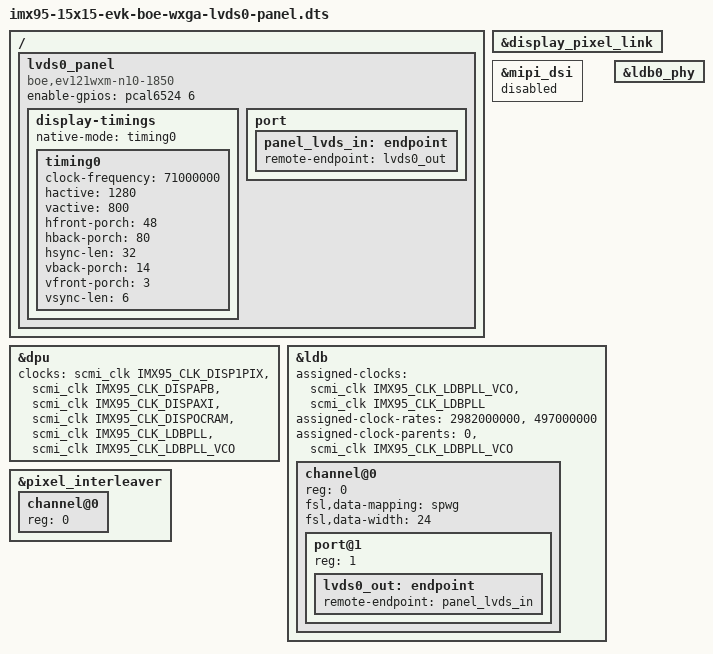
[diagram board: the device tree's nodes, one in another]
// SPDX-License-Identifier: (GPL-2.0+ OR MIT)
/*
 * Copyright 2024 NXP
 */

#include "imx95-15x15-evk.dts"
#include "imx95-15x15-evk-u-boot.dtsi"

/ {
	lvds0_panel {
		compatible = "boe,ev121wxm-n10-1850";
		enable-gpios = <&pcal6524 6 GPIO_ACTIVE_HIGH>;

		display-timings {
			native-mode = <&timing0>;

			timing0: timing0 {
				clock-frequency = <71000000>;
				hactive = <1280>;
				vactive = <800>;
				hfront-porch = <48>;
				hback-porch = <80>;
				hsync-len = <32>;
				vback-porch = <14>;
				vfront-porch = <3>;
				vsync-len = <6>;
			};
		};

		port {
			panel_lvds_in: endpoint {
				remote-endpoint = <&lvds0_out>;
			};
		};
	};
};

&display_pixel_link {
	status = "okay";
};

&dpu {
	clocks = <&scmi_clk IMX95_CLK_DISP1PIX>,
				 <&scmi_clk IMX95_CLK_DISPAPB>,
				 <&scmi_clk IMX95_CLK_DISPAXI>,
				 <&scmi_clk IMX95_CLK_DISPOCRAM>,
				 <&scmi_clk IMX95_CLK_LDBPLL>,
				 <&scmi_clk IMX95_CLK_LDBPLL_VCO>;
	status = "okay";
};

&mipi_dsi {
	status = "disabled";
};

&ldb {
	#address-cells = <1>;
	#size-cells = <0>;
	assigned-clocks = <&scmi_clk IMX95_CLK_LDBPLL_VCO>,
			  <&scmi_clk IMX95_CLK_LDBPLL>;
	assigned-clock-rates = <2982000000>, <497000000>;
	assigned-clock-parents = <0>, <&scmi_clk IMX95_CLK_LDBPLL_VCO>;
	status = "okay";

	channel@0 {
		#address-cells = <1>;
		#size-cells = <0>;
		reg = <0>;
		fsl,data-mapping = "spwg";
		fsl,data-width = <24>;
		status = "okay";

		port@1 {
			reg = <1>;

			lvds0_out: endpoint {
				remote-endpoint = <&panel_lvds_in>;
			};
		};
	};
};

&ldb0_phy {
	status = "okay";
};

&pixel_interleaver {
	#address-cells = <1>;
	#size-cells = <0>;
	status = "okay";

	channel@0 {
		reg = <0>;
		status = "okay";
	};
};
